# f28p65x_cmpss_regs register map
Vendor: Texas Instruments
Peripheral module from a debugger description file (folder C2000).
Address unit: 16 bits
Registers are 16-bit, read-write, no defined reset value unless marked. A register's access mark holds for its fields unless they carry their own. Offsets are as the file gives them; lines under a group give offsets from that group; [hi:lo] are bit positions; {n}, {i} and the like mark numbered series; 'fields as' and 'values as' point back to an identical list; <NAME> marks a mode.

## CMPSS_REGS — CMPSS Registers
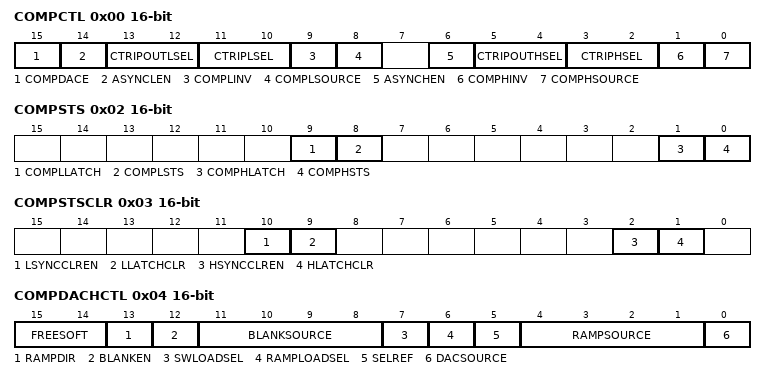
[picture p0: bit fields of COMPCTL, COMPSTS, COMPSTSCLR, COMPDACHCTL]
0x00 COMPCTL — CMPSS Comparator Control Register
  [15] COMPDACE — Comparator/DAC Enable
  [14] ASYNCLEN — Low Comparator Asynchronous Path Enable
  [13:12] CTRIPOUTLSEL — Low Comparator Trip Output Select
  [11:10] CTRIPLSEL — Low Comparator Trip Select
  [9] COMPLINV — Low Comparator Invert Select
  [8] COMPLSOURCE — Low Comparator Source Select
  [6] ASYNCHEN — High Comparator Asynchronous Path Enable
  [5:4] CTRIPOUTHSEL — High Comparator Trip Output Select
  [3:2] CTRIPHSEL — High Comparator Trip Select
  [1] COMPHINV — High Comparator Invert Select
  [0] COMPHSOURCE — High Comparator Source Select
0x01 COMPHYSCTL — CMPSS Comparator Hysteresis Control Register
  [3:0] COMPHYS — Comparator Hysteresis Trim
0x02 COMPSTS ro — CMPSS Comparator Status Register
  [9] COMPLLATCH — Low Comparator Latched Status
  [8] COMPLSTS — Low Comparator Status
  [1] COMPHLATCH — High Comparator Latched Status
  [0] COMPHSTS — High Comparator Status
0x03 COMPSTSCLR — CMPSS Comparator Status Clear Register
  [10] LSYNCCLREN — Low Comparator EPWMSYNCPER Clear Enable
  [9] LLATCHCLR — Low Comparator Latched Status Clear
  [2] HSYNCCLREN — High Comparator EPWMSYNCPER Clear Enable
  [1] HLATCHCLR — High Comparator Latched Status Clear
0x04 COMPDACHCTL — CMPSS High DAC Control Register
  [15:14] FREESOFT — Free/Soft Emulation Bits
  [13] RAMPDIR — Ramp Generator Direction
  [12] BLANKEN — EPWMBLANK Enable
  [11:8] BLANKSOURCE — EPWMBLANK Source Select
  [7] SWLOADSEL — Software Load Select
  [6] RAMPLOADSEL — Ramp Load Select
  [5] SELREF — DAC Reference Select
  [4:1] RAMPSOURCE — Ramp Generator Source Control
  [0] DACSOURCE — DAC Source Control
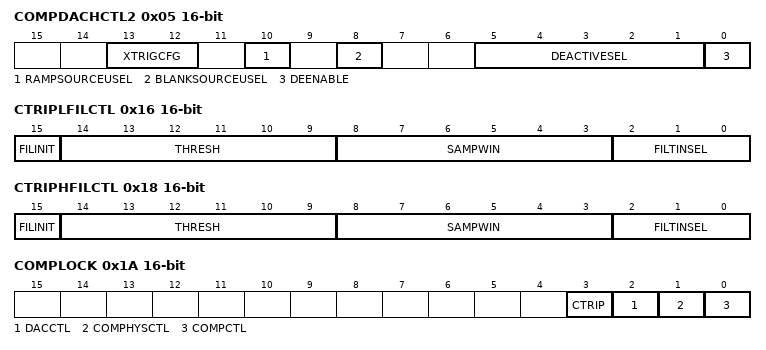
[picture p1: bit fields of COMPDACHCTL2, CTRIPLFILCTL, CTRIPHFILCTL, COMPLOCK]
0x05 COMPDACHCTL2 — CMPSS High DAC Control Register 2
  [13:12] XTRIGCFG — Ramp Generator Cross Trigger Configuration
  [10] RAMPSOURCEUSEL — RAMP source upper group select
  [8] BLANKSOURCEUSEL — BLANK source upper group select
  [5:1] DEACTIVESEL — DEACTIVE source select
  [0] DEENABLE — Diode Emulation mode enable
0x06 DACHVALS — CMPSS High DAC Value Shadow Register
  [11:0] DACVAL — DAC Value Control
0x07 DACHVALA ro — CMPSS High DAC Value Active Register
  [11:0] DACVAL — DAC Value Control
0x08 RAMPHREFA ro — CMPSS High Ramp Reference Active Register
  [15:0] RAMPHREF — High Ramp Reference Active
0x0A RAMPHREFS — CMPSS High Ramp Reference Shadow Register
  [15:0] RAMPHREF — High Ramp Reference Shadow
0x0C RAMPHSTEPVALA ro — CMPSS High Ramp Step Value Active Register
  [15:0] RAMPHSTEPVAL — High Ramp Step Value Active
0x0D RAMPHCTLA ro — CMPSS High Ramp Control Active Register
  [3:0] RAMPCLKDIV — Ramp Clock Divider Active Value
0x0E RAMPHSTEPVALS — CMPSS High Ramp Step Value Shadow Register
  [15:0] RAMPHSTEPVAL — High Ramp Step Value Shadow
0x0F RAMPHCTLS — CMPSS High Ramp Control Shadow Register
  [3:0] RAMPCLKDIV — Ramp Clock Divider Shadow Value
0x10 RAMPHSTS ro — CMPSS High Ramp Status Register
  [15:0] RAMPHVALUE — High Ramp Value
0x12 DACLVALS — CMPSS Low DAC Value Shadow Register
  [11:0] DACVAL — DAC Value Control
0x13 DACLVALA ro — CMPSS Low DAC Value Active Register
  [11:0] DACVAL — DAC Value Control
0x14 RAMPHDLYA ro — CMPSS High Ramp Delay Active Register
  [12:0] DELAY — High Ramp Delay Value Active
0x15 RAMPHDLYS — CMPSS High Ramp Delay Shadow Register
  [12:0] DELAY — High Ramp Delay Value Shadow
0x16 CTRIPLFILCTL — CTRIPL Filter Control Register
  [15] FILINIT — Filter Initialization Bit
  [14:9] THRESH — Majority Voting Threshold
  [8:3] SAMPWIN — Sample Window
  [2:0] FILTINSEL — Filter Input Select
0x17 CTRIPLFILCLKCTL — CTRIPL Filter Clock Control Register
  [15:0] CLKPRESCALE — Sample Clock Prescale
0x18 CTRIPHFILCTL — CTRIPH Filter Control Register
  fields as CTRIPLFILCTL
0x19 CTRIPHFILCLKCTL — CTRIPH Filter Clock Control Register
  [15:0] CLKPRESCALE — Sample Clock Prescale
0x1A COMPLOCK — CMPSS Lock Register
  [3] CTRIP — CTRIP Lock
  [2] DACCTL — DACCTL Lock
  [1] COMPHYSCTL — COMPHYSCTL Lock
  [0] COMPCTL — COMPCTL Lock
0x1C DACHVALS2 — CMPSS High DAC Value Shadow Register 2
  [11:0] DACVAL — DAC Value Control
0x1D DACLVALS2 — CMPSS Low DAC Value Shadow Register 2
  [11:0] DACVAL — DAC Value Control
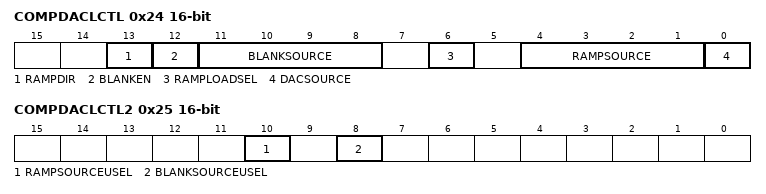
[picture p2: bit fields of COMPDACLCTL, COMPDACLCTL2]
0x24 COMPDACLCTL — CMPSS Low DAC Control Register
  [13] RAMPDIR — Ramp Generator Direction
  [12] BLANKEN — EPWMBLANK Enable
  [11:8] BLANKSOURCE — EPWMBLANK Source Select
  [6] RAMPLOADSEL — Ramp Load Select
  [4:1] RAMPSOURCE — Ramp Generator Source Control
  [0] DACSOURCE — DAC Source Control
0x25 COMPDACLCTL2 — CMPSS Low DAC Control Register 2
  [10] RAMPSOURCEUSEL — RAMP source upper group select
  [8] BLANKSOURCEUSEL — BLANK source upper group select
0x28 RAMPLREFA ro — CMPSS Low Ramp Reference Active Register
  [15:0] RAMPLREF — Low Ramp Reference Active
0x2A RAMPLREFS — CMPSS Low Ramp Reference Shadow Register
  [15:0] RAMPLREF — Low Ramp Reference Shadow
0x2C RAMPLSTEPVALA ro — CMPSS Low Ramp Step Value Active Register
  [15:0] RAMPLSTEPVAL — Low Ramp Step Value Active
0x2D RAMPLCTLA ro — CMPSS Low Ramp Control Active Register
  [3:0] RAMPCLKDIV — Ramp Clock Divider Active Value
0x2E RAMPLSTEPVALS — CMPSS Low Ramp Step Value Shadow Register
  [15:0] RAMPLSTEPVAL — Low Ramp Step Value Shadow
0x2F RAMPLCTLS — CMPSS Low Ramp Control Shadow Register
  [3:0] RAMPCLKDIV — Ramp Clock Divider Shadow Value
0x30 RAMPLSTS ro — CMPSS Low Ramp Status Register
  [15:0] RAMPLVALUE — Low Ramp Value
0x34 RAMPLDLYA ro — CMPSS Low Ramp Delay Active Register
  [12:0] DELAY — Low Ramp Delay Value Active
0x35 RAMPLDLYS — CMPSS Low Ramp Delay Shadow Register
  [12:0] DELAY — Low Ramp Delay Value Shadow
0x37 CTRIPLFILCLKCTL2 — CTRIPL Filter Clock Control Register 2
  [7:0] CLKPRESCALEU — Sample Clock Prescale Upper Bits
0x39 CTRIPHFILCLKCTL2 — CTRIPH Filter Clock Control Register 2
  [7:0] CLKPRESCALEU — Sample Clock Prescale Upper Bits
